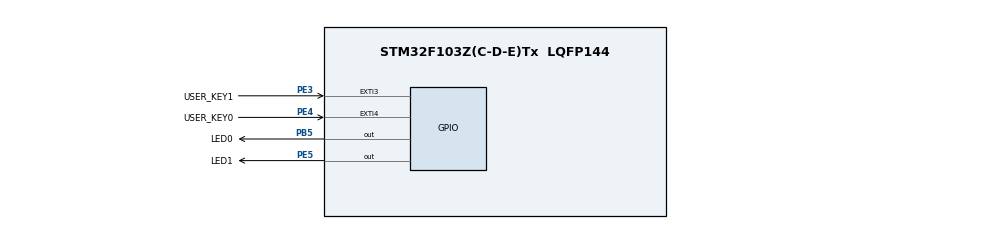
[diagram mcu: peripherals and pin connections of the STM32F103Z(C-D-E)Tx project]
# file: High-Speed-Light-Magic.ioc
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Mcu.Family=STM32F1
Mcu.Name=STM32F103Z(C-D-E)Tx
Mcu.Package=LQFP144
NVIC.EXTI3_IRQn=true\:2\:0\:true\:false\:true\:true\:true\:true
NVIC.EXTI4_IRQn=true\:0\:0\:false\:false\:true\:true\:true\:true
NVIC.PriorityGroup=NVIC_PRIORITYGROUP_4
OSC_IN.Mode=HSE-External-Oscillator
OSC_IN.Signal=RCC_OSC_IN
OSC_OUT.Mode=HSE-External-Oscillator
OSC_OUT.Signal=RCC_OSC_OUT
PA13.Mode=Serial_Wire
PA13.Signal=SYS_JTMS-SWDIO
PA14.Mode=Serial_Wire
PA14.Signal=SYS_JTCK-SWCLK
PB5.GPIO_Label=LED0
PB5.Signal=GPIO_Output
PE3.GPIO_Label=USER_KEY1
PE3.GPIO_ModeDefaultEXTI=GPIO_MODE_IT_RISING_FALLING
PE3.GPIO_PuPd=GPIO_PULLUP
PE3.Signal=GPXTI3
PE4.GPIO_Label=USER_KEY0
PE4.Signal=GPXTI4
PE5.GPIO_Label=LED1
PE5.Signal=GPIO_Output
ProjectManager.HeapSize=0x200
ProjectManager.StackSize=0x400
ProjectManager.TargetToolchain=CMake
RCC.APB1Freq_Value=8000000
RCC.APB2Freq_Value=8000000
board=custom

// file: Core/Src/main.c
/* USER CODE BEGIN Header */
/**
  ******************************************************************************
  * @file           : main.c
  * @brief          : Main program body
  ******************************************************************************
  * @attention
  *
  * Copyright (c) 2026 STMicroelectronics.
  * All rights reserved.
  *
  * This software is licensed under terms that can be found in the LICENSE file
  * in the root directory of this software component.
  * If no LICENSE file comes with this software, it is provided AS-IS.
  *
  ******************************************************************************
  */
/* USER CODE END Header */
#include "main.h"
#include "gpio.h"

void SystemClock_Config(void);

/* USER CODE BEGIN 0 */
volatile uint8_t mode = 0;
/* USER CODE END 0 */

int main(void)
{

  /* MCU Configuration--------------------------------------------------------*/

  /* Reset of all peripherals, Initializes the Flash interface and the Systick. */
  HAL_Init();

  /* Configure the system clock */
  SystemClock_Config();

  /* Initialize all configured peripherals */
  MX_GPIO_Init();
  /* USER CODE BEGIN 2 */
  HAL_GPIO_WritePin(GPIOB, GPIO_PIN_5, GPIO_PIN_SET);
  HAL_GPIO_WritePin(GPIOE, GPIO_PIN_5, GPIO_PIN_SET);

  /* USER CODE END 2 */

  /* Infinite loop */
  while (1){

    /* USER CODE BEGIN 3 */
    if (mode == 1)
    {
      HAL_Delay(5000);
      HAL_GPIO_WritePin(GPIOE, GPIO_PIN_5, GPIO_PIN_RESET);
    }

  }
  /* USER CODE END 3 */
}

void SystemClock_Config(void)
{
  RCC_OscInitTypeDef RCC_OscInitStruct = {0};
  RCC_ClkInitTypeDef RCC_ClkInitStruct = {0};

  /** Initializes the RCC Oscillators according to the specified parameters
  * in the RCC_OscInitTypeDef structure.
  */
  RCC_OscInitStruct.OscillatorType = RCC_OSCILLATORTYPE_HSI;
  RCC_OscInitStruct.HSIState = RCC_HSI_ON;
  RCC_OscInitStruct.HSICalibrationValue = RCC_HSICALIBRATION_DEFAULT;
  RCC_OscInitStruct.PLL.PLLState = RCC_PLL_NONE;
  if (HAL_RCC_OscConfig(&RCC_OscInitStruct) != HAL_OK)
  {
    Error_Handler();
  }

  /** Initializes the CPU, AHB and APB buses clocks
  */
  RCC_ClkInitStruct.ClockType = RCC_CLOCKTYPE_HCLK|RCC_CLOCKTYPE_SYSCLK
                              |RCC_CLOCKTYPE_PCLK1|RCC_CLOCKTYPE_PCLK2;
  RCC_ClkInitStruct.SYSCLKSource = RCC_SYSCLKSOURCE_HSI;
  RCC_ClkInitStruct.AHBCLKDivider = RCC_SYSCLK_DIV1;
  RCC_ClkInitStruct.APB1CLKDivider = RCC_HCLK_DIV1;
  RCC_ClkInitStruct.APB2CLKDivider = RCC_HCLK_DIV1;

  if (HAL_RCC_ClockConfig(&RCC_ClkInitStruct, FLASH_LATENCY_0) != HAL_OK)
  {
    Error_Handler();
  }
}

/* USER CODE BEGIN 4 */
void HAL_GPIO_EXTI_Callback(uint16_t GPIO_Pin)
{
  if (GPIO_Pin == GPIO_PIN_3)
  {
    mode = 1;
  }
  if (GPIO_Pin == GPIO_PIN_4)
  {
    HAL_GPIO_WritePin(GPIOE, GPIO_PIN_5, GPIO_PIN_RESET);
  }
}
/* USER CODE END 4 */

void Error_Handler(void)
{
  __disable_irq();
  while (1)
  {
  }
}
